# STM32C562xx register map
File version: 1.0
Registers are 32-bit, read-write, reset 0x0 unless marked. A register's access mark holds for its fields unless they carry their own. Offsets are from the block's base; [hi:lo] are bit positions; {n}, {i} and the like mark numbered series; 'fields as' and 'values as' point back to an identical list.

## CORDIC
Base 0x40023800
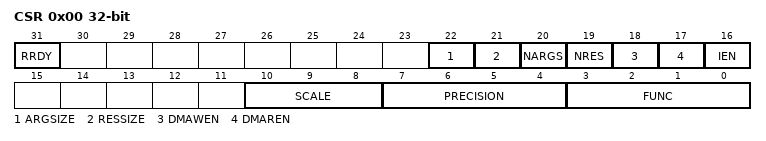
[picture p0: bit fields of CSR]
0x00 CSR — CORDIC control and status register
  [31] RRDY — Result Ready Flag
  [22] ARGSIZE — Width of input data
  [21] RESSIZE — Width of output data
  [20] NARGS — Number of arguments in RDATA register
  [19] NRES — Number of results in WDATA register
  [18] DMAWEN — DMA Write channel Enable
  [17] DMAREN — DMA Read channel Enable
  [16] IEN — Interrupt Enable
  [10:8] SCALE — Scaling factor
  [7:4] PRECISION
  [3:0] FUNC — Function
0x04 WDATA — CORDIC argument register
  [31:0] ARG — Input Argument
0x08 RDATA ro — CORDIC result register
  [31:0] RES — Output Result

## RAMCFG
Base 0x40026000
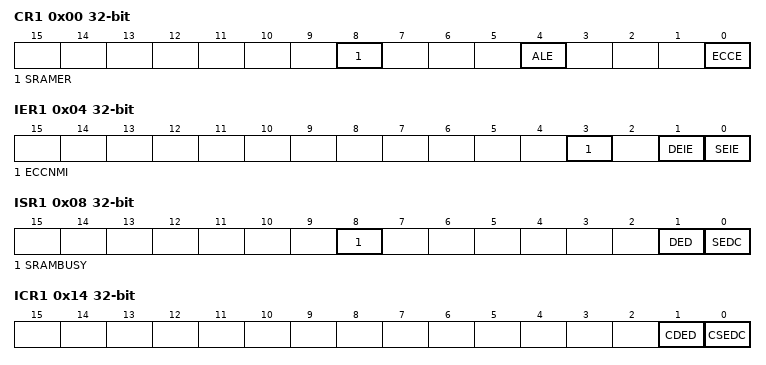
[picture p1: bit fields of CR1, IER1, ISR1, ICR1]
0x00 CR1 — RAMCFG control register
  [8] SRAMER — SRAM erase
  [4] ALE — Address latch enable
  [0] ECCE — ECC enable
0x04 IER1 — RAMCFG interrupt enable register
  [3] ECCNMI — Double error NMI
  [1] DEIE — ECC double error interrupt enable
  [0] SEIE — ECC single error interrupt enable
0x08 ISR1 ro — RAMCFG interrupt status register
  [8] SRAMBUSY — SRAM busy with erase operation
  [1] DED — ECC double error detected
  [0] SEDC
0x0C SEAR1 ro — RAMCFG ECC single error address register
  [31:0] ESEA — ECC single error address
0x10 DEAR1 ro — RAMCFG ECC double error address register
  [31:0] EDEA — ECC double error address
0x14 ICR1 — RAMCFG interrupt clear register
  [1] CDED — Clear ECC double error detected
  [0] CSEDC
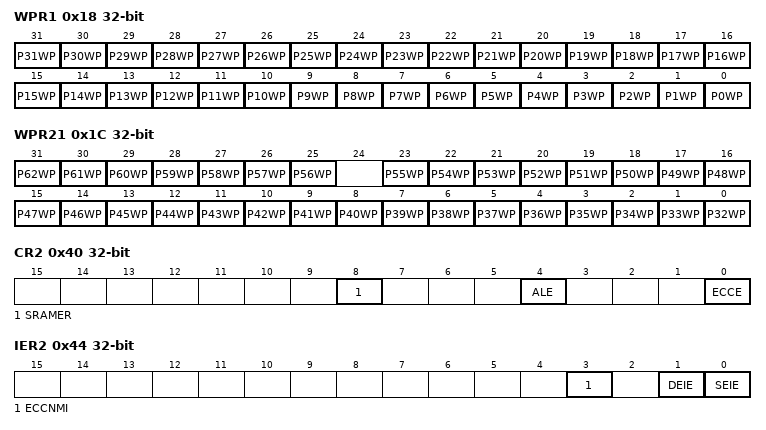
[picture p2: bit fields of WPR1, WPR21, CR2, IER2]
0x18 WPR1 — RAMCFG write protection register 1
  [n] P{n}WP (n=0..31) — Write Protection Page {n:02}
0x1C WPR21 — RAMCFG write protection register 2
  [n-31] P{n}WP (n=56..62) — Write Protection Page {n}
  [n-32] P{n}WP (n=32..55) — Write Protection Page {n}
0x24 ECCKEYR1 — RAMCFG ECC key register
  [7:0] ECCKEY — ECC write protection key
0x28 ERKEYR1 — RAMCFG erase key register
  [7:0] ERASEKEY — Erase write protection key
0x40 CR2 — RAMCFG control register
  fields as CR1
0x44 IER2 — RAMCFG interrupt enable register
  fields as IER1
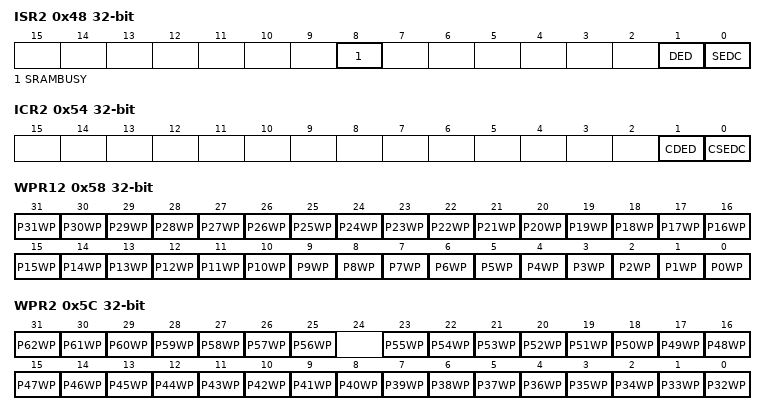
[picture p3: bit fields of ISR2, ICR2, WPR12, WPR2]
0x48 ISR2 ro — RAMCFG interrupt status register
  fields as ISR1
0x4C SEAR2 ro — RAMCFG ECC single error address register
  [31:0] ESEA — ECC single error address
0x50 DEAR2 ro — RAMCFG ECC double error address register
  [31:0] EDEA — ECC double error address
0x54 ICR2 — RAMCFG interrupt clear register
  [1] CDED — Clear ECC double error detected
  [0] CSEDC
0x58 WPR12 — RAMCFG write protection register 1
  [n] P{n}WP (n=0..31) — Write Protection Page {n:02}
0x5C WPR2 — RAMCFG write protection register 2
  fields as WPR21
0x64 ECCKEYR2 — RAMCFG ECC key register
  [7:0] ECCKEY — ECC write protection key
0x68 ERKEYR2 — RAMCFG erase key register
  [7:0] ERASEKEY — Erase write protection key

## ICACHE — Instruction cache (ICACHE)
Base 0x40030400
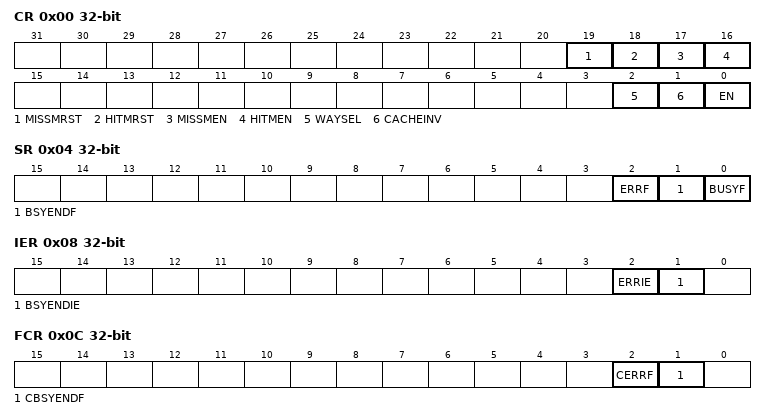
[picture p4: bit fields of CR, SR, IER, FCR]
0x00 CR — ICACHE control register
  [19] MISSMRST — miss monitor reset
  [18] HITMRST — hit monitor reset
  [17] MISSMEN — miss monitor enable
  [16] HITMEN — hit monitor enable
  [2] WAYSEL — cache associativity mode selection
  [1] CACHEINV — cache invalidation
  [0] EN — enable
0x04 SR ro — ICACHE status register
  [2] ERRF — cache error flag
  [1] BSYENDF — busy end flag
  [0] BUSYF — busy flag
0x08 IER — ICACHE interrupt enable register
  [2] ERRIE — interrupt enable on cache error
  [1] BSYENDIE — interrupt enable on busy end
0x0C FCR — ICACHE flag clear register
  [2] CERRF — clear cache error flag
  [1] CBSYENDF — clear busy end flag
0x10 HMONR ro — ICACHE hit monitor register
  [31:0] HITMON — cache hit monitor counter
0x14 MMONR ro — ICACHE miss monitor register
  [15:0] MISSMON — cache miss monitor counter
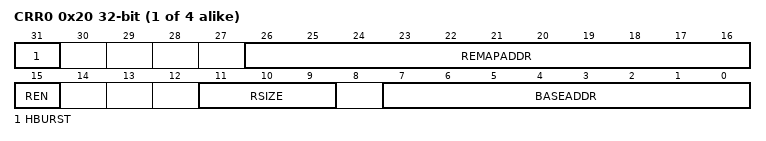
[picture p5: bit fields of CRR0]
{0x20+4i} CRR{i} (i=0..3) — ICACHE region {i} configuration register
  [31] HBURST — output burst type for region x
  [26:16] REMAPADDR — remapped address for region x
  [15] REN — enable for region x
  [11:9] RSIZE — size for region x
  [7:0] BASEADDR — base address for region x
